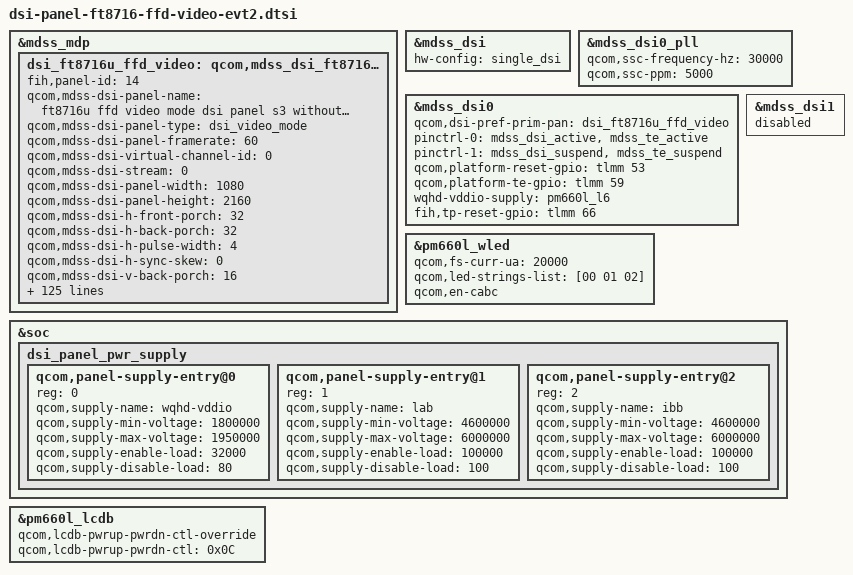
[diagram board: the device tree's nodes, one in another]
/* Copyright (c) 2015, The Linux Foundation. All rights reserved.
 *
 * This program is free software; you can redistribute it and/or modify
 * it under the terms of the GNU General Public License version 2 and
 * only version 2 as published by the Free Software Foundation.
 *
 * This program is distributed in the hope that it will be useful,
 * but WITHOUT ANY WARRANTY; without even the implied warranty of
 * MERCHANTABILITY or FITNESS FOR A PARTICULAR PURPOSE.  See the
 * GNU General Public License for more details.
 */

/*---------------------------------------------------------------------------
 * Templated from dsi-panel-r69006-1080p-video.dtsi
 *---------------------------------------------------------------------------*/
&mdss_mdp {
	/delete-node/ qcom,mdss_dsi_ft8716_ffd_video_s2;
	dsi_ft8716u_ffd_video: qcom,mdss_dsi_ft8716u_ffd_video_s3 {
		fih,panel-id = <14>;
		qcom,mdss-dsi-panel-name = "ft8716u ffd video mode dsi panel s3 without DSC";
		qcom,mdss-dsi-panel-type = "dsi_video_mode";
		qcom,mdss-dsi-panel-framerate = <60>;
		qcom,mdss-dsi-virtual-channel-id = <0>;
		qcom,mdss-dsi-stream = <0>;
		qcom,mdss-dsi-panel-width = <1080>;
		qcom,mdss-dsi-panel-height = <2160>;
		qcom,mdss-dsi-h-front-porch = <32>;
		qcom,mdss-dsi-h-back-porch = <32>;
		qcom,mdss-dsi-h-pulse-width = <4>;
		qcom,mdss-dsi-h-sync-skew = <0>;
		qcom,mdss-dsi-v-back-porch = <16>;
		qcom,mdss-dsi-v-front-porch = <16>;
		qcom,mdss-dsi-v-pulse-width = <2>;
		qcom,mdss-dsi-h-left-border = <0>;
		qcom,mdss-dsi-h-right-border = <0>;
		qcom,mdss-dsi-v-top-border = <0>;
		qcom,mdss-dsi-v-bottom-border = <0>;
		qcom,mdss-dsi-bpp = <24>;
		qcom,mdss-dsi-underflow-color = <0xff>;
		qcom,mdss-dsi-border-color = <0>;
		qcom,mdss-dsi-on-command = [
			// ENABLE CMD2
			29 00 00 00 00 00 04 FF 87 16 01
			29 00 00 00 00 00 02 00 80
			29 01 00 00 00 00 03 FF 87 16
			// GAMMA
			29 00 00 00 00 00 02 00 80
			29 01 00 00 00 00 0D D8 00 81 81 82 85 86 87 87 87 86 85 83
			29 00 00 00 00 00 02 00 90
			29 01 00 00 00 00 0D D8 01 02 02 03 06 07 08 0a 0a 0b 0c 0b
			29 00 00 00 00 00 02 00 A0
			29 01 00 00 00 00 0D D8 00 01 02 02 02 03 04 07 0a 0c 0c 0f
			29 00 00 00 00 00 02 00 B0
			29 01 00 00 00 00 0D D8 00 00 81 81 80 81 81 82 84 85 83 85
			29 00 00 00 00 00 02 00 C0
			29 01 00 00 00 00 0D D8 85 8b 90 96 a1 ad b7 bf ca cd ca cf
			29 00 00 00 00 00 02 00 D0
			29 01 00 00 00 00 0D D8 02 04 06 08 0c 10 14 18 1a 1c 1b 1c
			29 00 00 00 00 00 02 00 E0
			29 01 00 00 00 00 04 D8 f7 f2 eb
			29 00 00 00 00 00 02 00 C0
			29 01 00 00 00 00 02 D7 41
			// DGAMMA OFF
			29 00 00 00 00 00 02 00 A0
			29 01 00 00 00 00 02 D7 05
			// Typical White Point
			29 00 00 00 00 00 02 00 00
			29 01 00 00 00 00 02 94 00
			// CE
			29 00 00 00 00 00 02 00 A0
			29 01 00 00 00 00 0D D6 0F 0D 0E 0B 0E 0B 0F 11 16 16 13 12
			29 00 00 00 00 00 02 00 B0
			29 01 00 00 00 00 0D D6 B1 9A FF F6 F5 E9 AB C1 E4 E7 F6 F0
			29 00 00 00 00 00 02 00 C0
			29 01 00 00 00 00 0D D6 A0 8D D4 CE CE C6 9D AB C3 C5 CF CA
			29 00 00 00 00 00 02 00 D0
			29 01 00 00 00 00 0D D6 91 83 AA A7 A7 A3 8E 96 A1 A2 A7 A5
			// CE off
			29 00 00 00 00 00 02 00 00
			29 01 00 00 00 00 03 91 00 00
			/* C590H  - power control setting */
			29 00 00 00 00 00 02 00 90
			29 01 00 00 00 00 0B C5 44 24 14 C0 88 00 2E 37 55 50
			/* Set CABC backlight min & max for UI, ST, MV mode */
			39 01 00 00 00 00 02 00 80
			39 01 00 00 00 00 0B CA 80 CC FF A5 FF 80 FF 00 00 00
			/* Set 53h Dimming frame CAB5 */
			39 01 00 00 00 00 02 00 B5
			39 01 00 00 00 00 02 CA 01
			// DISABLE CMD2
			29 00 00 00 00 00 02 00 00
			29 01 00 00 00 00 04 FF 00 00 00
			// ??
			29 00 00 00 00 00 02 00 80
			29 01 00 00 00 00 03 FF 00 00
			// DSI ON
			05 01 00 00 78 00 02 11 00
			05 01 00 00 0a 00 02 35 00
			05 01 00 00 00 00 02 29 00
			15 01 00 00 00 00 02 53 2C
			15 01 00 00 00 00 03 51 FF 03
		];
		qcom,mdss-dsi-off-command = [
			05 01 00 00 14 00 02 28 00
			05 01 00 00 78 00 02 10 00
		];
		qcom,mdss-dsi-ct-normal-command = [
			// Enable CMD2
			29 00 00 00 00 00 04 FF 87 16 01
			29 00 00 00 00 00 02 00 80
			29 01 00 00 00 00 03 FF 87 16
			// Gamma Channel
			29 00 00 00 00 00 02 00 A0
			29 01 00 00 00 00 02 D7 05
			// Select White Point
			29 00 00 00 00 00 02 00 00
			29 01 00 00 00 00 02 94 00
			// Disable CMD2
			29 00 00 00 00 00 02 00 00
			29 00 00 00 00 00 04 FF 00 00 00
			29 00 00 00 00 00 02 00 80
			29 01 00 00 00 00 03 FF 00 00
		];

		qcom,mdss-dsi-ct-warm-command = [
			// Enable CMD2
			29 00 00 00 00 00 04 FF 87 16 01
			29 00 00 00 00 00 02 00 80
			29 01 00 00 00 00 03 FF 87 16
			// Gamma Channel
			29 00 00 00 00 00 02 00 A0
			29 01 00 00 00 00 02 D7 05
			// Select White Point
			29 00 00 00 00 00 02 00 00
			29 01 00 00 00 00 02 94 D0
			// Disable CMD2
			29 00 00 00 00 00 02 00 00
			29 00 00 00 00 00 04 FF 00 00 00
			29 00 00 00 00 00 02 00 80
			29 01 00 00 00 00 03 FF 00 00
		];

		qcom,mdss-dsi-ct-cold-command = [
			// Enable CMD2
			29 00 00 00 00 00 04 FF 87 16 01
			29 00 00 00 00 00 02 00 80
			29 01 00 00 00 00 03 FF 87 16
			// Gamma Channel
			29 00 00 00 00 00 02 00 A0
			29 01 00 00 00 00 02 D7 05
			// Select White Point
			29 00 00 00 00 00 02 00 00
			29 01 00 00 00 00 02 94 AA
			// Disable CMD2
			29 00 00 00 00 00 02 00 00
			29 00 00 00 00 00 04 FF 00 00 00
			29 00 00 00 00 00 02 00 80
			29 01 00 00 00 00 03 FF 00 00
		];

		qcom,mdss-dsi-blf-10-command = [
			// Enable CMD2
			29 00 00 00 00 00 04 FF 87 16 01
			29 00 00 00 00 00 02 00 80
			29 01 00 00 00 00 03 FF 87 16
			// Gamma Channel
			29 00 00 00 00 00 02 00 A0
			29 01 00 00 00 00 02 D7 05
			// Select White Point
			29 00 00 00 00 00 02 00 00
			29 01 00 00 00 00 02 94 C8
			// Disable CMD2
			29 00 00 00 00 00 02 00 00
			29 00 00 00 00 00 04 FF 00 00 00
			29 00 00 00 00 00 02 00 80
			29 01 00 00 00 00 03 FF 00 00
		];

		qcom,mdss-dsi-blf-30-command = [
			// Enable CMD2
			29 00 00 00 00 00 04 FF 87 16 01
			29 00 00 00 00 00 02 00 80
			29 01 00 00 00 00 03 FF 87 16
			// Gamma Channel
			29 00 00 00 00 00 02 00 A0
			29 01 00 00 00 00 02 D7 05
			// Select White Point
			29 00 00 00 00 00 02 00 00
			29 01 00 00 00 00 02 94 D7
			// Disable CMD2
			29 00 00 00 00 00 02 00 00
			29 00 00 00 00 00 04 FF 00 00 00
			29 00 00 00 00 00 02 00 80
			29 01 00 00 00 00 03 FF 00 00
		];

		qcom,mdss-dsi-blf-50-command = [
			// Enable CMD2
			29 00 00 00 00 00 04 FF 87 16 01
			29 00 00 00 00 00 02 00 80
			29 01 00 00 00 00 03 FF 87 16
			// Gamma Channel
			29 00 00 00 00 00 02 00 A0
			29 01 00 00 00 00 02 D7 05
			// Select White Point
			29 00 00 00 00 00 02 00 00
			29 01 00 00 00 00 02 94 F0
			// Disable CMD2
			29 00 00 00 00 00 02 00 00
			29 00 00 00 00 00 04 FF 00 00 00
			29 00 00 00 00 00 02 00 80
			29 01 00 00 00 00 03 FF 00 00
		];

		qcom,mdss-dsi-blf-75-command = [
			// Enable CMD2
			29 00 00 00 00 00 04 FF 87 16 01
			29 00 00 00 00 00 02 00 80
			29 01 00 00 00 00 03 FF 87 16
			// Gamma Channel
			29 00 00 00 00 00 02 00 A0
			29 01 00 00 00 00 02 D7 05
			// Select White Point
			29 00 00 00 00 00 02 00 00
			29 01 00 00 00 00 02 94 FF
			// Disable CMD2
			29 00 00 00 00 00 02 00 00
			29 00 00 00 00 00 04 FF 00 00 00
			29 00 00 00 00 00 02 00 80
			29 01 00 00 00 00 03 FF 00 00
		];

		qcom,mdss-dsi-on-command-state = "dsi_lp_mode";
		qcom,mdss-dsi-off-command-state = "dsi_hs_mode";
		qcom,mdss-dsi-ct-normal-command-state = "dsi_lp_mode";
		qcom,mdss-dsi-ct-warm-command-state = "dsi_lp_mode";
		qcom,mdss-dsi-ct-cold-command-state = "dsi_lp_mode";
		qcom,mdss-dsi-blf-10-command-state = "dsi_lp_mode";
		qcom,mdss-dsi-blf-30-command-state = "dsi_lp_mode";
		qcom,mdss-dsi-blf-50-command-state = "dsi_lp_mode";
		qcom,mdss-dsi-blf-75-command-state = "dsi_lp_mode";

		qcom,mdss-dsi-cabc-off-command = [
			39 01 00 00 00 00 02 55 00
		];

		qcom,mdss-dsi-cabc-ui-command = [
			39 01 00 00 00 00 02 55 01
		];

		qcom,mdss-dsi-cabc-still-command = [
			39 01 00 00 00 00 02 55 02
		];

		qcom,mdss-dsi-cabc-moving-command = [
			39 01 00 00 00 00 02 55 03
		];

		qcom,mdss-dsi-cabc-off-command-state = "dsi_hs_mode";
		qcom,mdss-dsi-cabc-ui-command-state = "dsi_hs_mode";
		qcom,mdss-dsi-cabc-still-command-state = "dsi_hs_mode";
		qcom,mdss-dsi-cabc-moving-command-state = "dsi_hs_mode";

		qcom,mdss-dsi-cabc-off-command-BeforeInit = [
			39 01 00 00 00 00 02 55 00
		];

		qcom,mdss-dsi-cabc-ui-command-BeforeInit = [
			39 01 00 00 00 00 02 55 01
		];

		qcom,mdss-dsi-cabc-still-command-BeforeInit = [
			39 01 00 00 00 00 02 55 02
		];

		qcom,mdss-dsi-cabc-moving-command-BeforeInit = [
			39 01 00 00 00 00 02 55 03
		];

		qcom,mdss-dsi-cabc-off-command-BeforeInit-state = "dsi_lp_mode";
		qcom,mdss-dsi-cabc-ui-command-BeforeInit-state = "dsi_lp_mode";
		qcom,mdss-dsi-cabc-still-command-BeforeInit-state = "dsi_lp_mode";
		qcom,mdss-dsi-cabc-moving-command-BeforeInit-state = "dsi_lp_mode";

		// dynamic : value 1
		qcom,mdss-dsi-ce-on-command = [
			29 01 00 00 00 00 03 91 80 00
		];

		// standard : value 0
		qcom,mdss-dsi-ce-off-command = [
			29 01 00 00 00 00 03 91 00 00
		];

		qcom,mdss-dsi-ce-on-command-state = "dsi_hs_mode";
		qcom,mdss-dsi-ce-off-command-state = "dsi_hs_mode";

		fih,mdss-dsi-write-reg-command = [
			39 01 00 00 00 00 04 00 00 00 00
		];

		fih,mdss-dsi-write-reg-command-state = "dsi_lp_mode";

		qcom,mdss-dsi-h-sync-pulse = <0>;
		qcom,mdss-dsi-traffic-mode = "non_burst_sync_event";
		qcom,mdss-dsi-bllp-eof-power-mode;
		qcom,mdss-dsi-bllp-power-mode;
		qcom,mdss-dsi-lane-0-state;
		qcom,mdss-dsi-lane-1-state;
		qcom,mdss-dsi-lane-2-state;
		qcom,mdss-dsi-lane-3-state;
		qcom,mdss-dsi-t-clk-post = <0x0d>;
		qcom,mdss-dsi-t-clk-pre = <0x2d>;
		qcom,esd-check-enabled;
		qcom,mdss-dsi-panel-status-check-mode = "reg_read";
		qcom,mdss-dsi-panel-status-command = [
			06 01 00 01 00 00 01 0a
			06 01 00 01 00 00 01 0b
			06 01 00 01 00 00 01 0c
			06 01 00 01 00 00 01 0d
			06 01 00 01 00 00 01 ac
		];
		qcom,mdss-dsi-panel-status-command-state = "dsi_hs_mode";
		qcom,mdss-dsi-panel-status-value = <0x9c>,<0x00>,<0x07>,<0x00>,<0x00>;
		qcom,mdss-dsi-panel-on-check-value = <0x9c>,<0x00>,<0x07>,<0x00>,<0x00>;
		qcom,mdss-dsi-panel-status-read-length = <1>,<1>,<1>,<1>,<1>;
		qcom,mdss-dsi-panel-max-error-count = <3>;
		qcom,mdss-dsi-dma-trigger = "trigger_sw";
		qcom,mdss-dsi-mdp-trigger = "none";
		qcom,mdss-dsi-reset-sequence = <1 1>, <0 1>, <1 15>;

		qcom,mdss-pan-physical-width-dimension = <68>;
		qcom,mdss-pan-physical-height-dimension = <136>;
		qcom,suspend-ulps-enabled;
	};
};

&dsi_ft8716u_ffd_video {
	qcom,mdss-dsi-panel-timings-phy-v2 = [
		23 1f 07 09 05 03 04 a0
		23 1f 07 09 05 03 04 a0
		23 1f 07 09 05 03 04 a0
		23 1f 07 09 05 03 04 a0
		23 19 08 08 05 03 04 a0
	];
	qcom,mdss-dsi-bl-pmic-control-type = "bl_ctrl_wled";
	qcom,mdss-dsi-bl-min-level = <1>;
	qcom,mdss-dsi-bl-max-level = <4095>;
	qcom,panel-supply-entries = <&dsi_panel_pwr_supply>;
};

&mdss_dsi {
	hw-config = "single_dsi";
};

&mdss_dsi0_pll {
	qcom,ssc-frequency-hz = <30000>;
	qcom,ssc-ppm = <5000>;
};

&mdss_dsi0 {
	qcom,dsi-pref-prim-pan = <&dsi_ft8716u_ffd_video>;
	pinctrl-names = "mdss_default", "mdss_sleep";
	pinctrl-0 = <&mdss_dsi_active &mdss_te_active>;
	pinctrl-1 = <&mdss_dsi_suspend &mdss_te_suspend>;
	qcom,platform-reset-gpio = <&tlmm 53 0>;
	qcom,platform-te-gpio = <&tlmm 59 0>;
	wqhd-vddio-supply = <&pm660l_l6>;
        fih,tp-reset-gpio = <&tlmm 66 0>;
};

&mdss_dsi1 {
	status = "disabled";
};

&pm660l_wled {
	qcom,fs-curr-ua = <20000>;
	qcom,led-strings-list = [00 01 02];
	qcom,en-cabc;
};

&soc {
	/delete-node/ dsi_panel_pwr_supply;
	dsi_panel_pwr_supply: dsi_panel_pwr_supply {
		#address-cells = <1>;
		#size-cells = <0>;

		qcom,panel-supply-entry@0 {
			reg = <0>;
			qcom,supply-name = "wqhd-vddio";
			qcom,supply-min-voltage = <1800000>;
			qcom,supply-max-voltage = <1950000>;
			qcom,supply-enable-load = <32000>;
			qcom,supply-disable-load = <80>;
		};

		qcom,panel-supply-entry@1 {
			reg = <1>;
			qcom,supply-name = "lab";
			qcom,supply-min-voltage = <4600000>;
			qcom,supply-max-voltage = <6000000>;
			qcom,supply-enable-load = <100000>;
			qcom,supply-disable-load = <100>;
		};

		qcom,panel-supply-entry@2 {
			reg = <2>;
			qcom,supply-name = "ibb";
			qcom,supply-min-voltage = <4600000>;
			qcom,supply-max-voltage = <6000000>;
			qcom,supply-enable-load = <100000>;
			qcom,supply-disable-load = <100>;
		};
	};
};

&pm660l_lcdb {
	qcom,lcdb-pwrup-pwrdn-ctl-override;
	qcom,lcdb-pwrup-pwrdn-ctl = /bits/ 8 <0x0C>;
};
